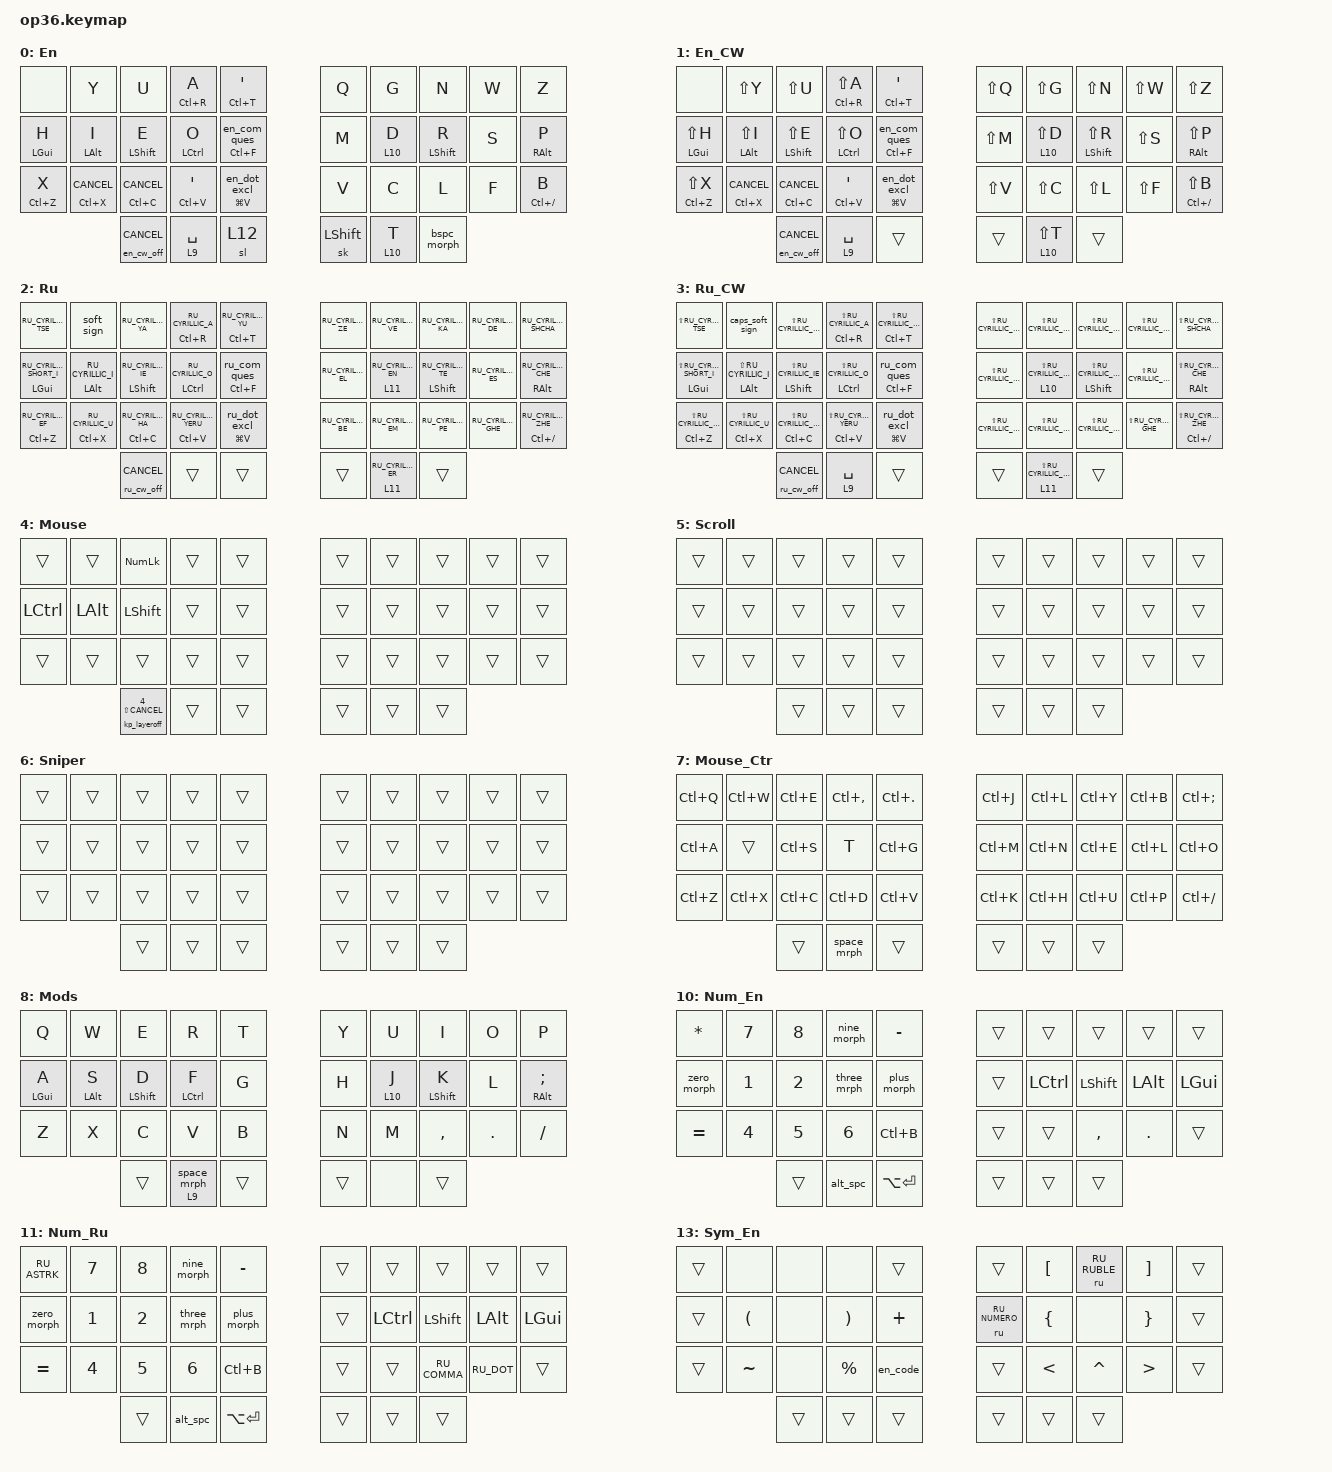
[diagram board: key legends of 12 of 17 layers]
#include "keys_ru.h"
#include <dt-bindings/zmk/behaviors.h>
#include <behaviors.dtsi>
#include <dt-bindings/zmk/bt.h>
#include <dt-bindings/zmk/keys.h>
#include <dt-bindings/zmk/outputs.h>
#include <dt-bindings/zmk/pointing.h>

&mt {
    flavor = "tap-preferred";
    tapping-term-ms = <200>;
    bindings = <&kp>, <&kp>;
};

&lt {
    flavor = "balanced";
    bindings = <&mo>, <&long_kp>;
};

&sl { release-after-ms = <5000>; };

&sk {
    release-after-ms = <5000>;
    quick-release;
};

&key_repeat { usage-pages = <HID_USAGE_KEY HID_USAGE_CONSUMER>; };

/ {
    combos {
        compatible = "zmk,combos";

        combo_ctrl_ent {
            bindings = <&kp LC(ENTER)>;
            key-positions = <1 3>;
            require-prior-idle-ms = <30>;
        };

        combo_enter {
            bindings = <&kp ENTER>;
            key-positions = <2 1>;
            require-prior-idle-ms = <30>;
            timeout-ms = <30>;
        };

        combo_tab {
            bindings = <&kp TAB>;
            key-positions = <11 12>;
            require-prior-idle-ms = <50>;
            timeout-ms = <30>;
        };

        combo_esc {
            bindings = <&kp ESC>;
            key-positions = <21 22>;
            require-prior-idle-ms = <30>;
            timeout-ms = <30>;
        };

        combo_ru {
            bindings = <&layer_ru>;
            key-positions = <23 22>;
            timeout-ms = <30>;
            require-prior-idle-ms = <(-1)>;
        };

        combo_en {
            bindings = <&layer_en>;
            key-positions = <26 27>;
            timeout-ms = <30>;
            require-prior-idle-ms = <(-1)>;
        };

        combo_osl_sym_en {
            bindings = <&sl 13>;
            key-positions = <16 17>;
            require-prior-idle-ms = <50>;
            layers = <0 1 13>;
        };

        combo_lessgreater_en {
            bindings = <&less_greater_en>;
            require-prior-idle-ms = <30>;
            key-positions = <26 28>;
            layers = <0 1 13>;
        };

        combo_osl_sym_ru {
            bindings = <&sl 14>;
            key-positions = <16 17>;
            require-prior-idle-ms = <50>;
            layers = <2 3 14>;
        };

        combo_lessgreater_ru {
            bindings = <&less_greater_ru>;
            key-positions = <26 28>;
            require-prior-idle-ms = <30>;
            layers = <2 3>;
        };

        combo_braces_en {
            bindings = <&braces_en>;
            key-positions = <16 18>;
            require-prior-idle-ms = <50>;
            layers = <0 1 13>;
        };

        combo_singlequote_ru {
            bindings = <&en SINGLE_QUOTE>;
            timeout-ms = <30>;
            key-positions = <6 5>;
            layers = <2 3 14 11>;
        };

        combo_slash_ru {
            bindings = <&kp RU_SLASH>;
            timeout-ms = <30>;
            key-positions = <27 28>;
            layers = <2 3 14 11>;
        };

        combo_singequote_en {
            bindings = <&kp SINGLE_QUOTE>;
            timeout-ms = <30>;
            key-positions = <6 5>;
            layers = <0 1 10 13>;
        };

        combo_slash_en {
            bindings = <&kp SLASH>;
            timeout-ms = <30>;
            key-positions = <27 28>;
            layers = <0 1 10 13>;
        };

        combo_capsword_en {
            bindings = <&to 1>;
            key-positions = <11 10>;
            layers = <0 1>;
        };

        combo_osl_fn {
            bindings = <&sl 15>;
            key-positions = <21 23>;
        };

        combo_osl_os {
            bindings = <&sl 16>;
            key-positions = <20 21>;
        };

        combo_capsword_ru {
            bindings = <&to 3>;
            key-positions = <11 10>;
            layers = <2 3>;
        };

        combo_yo_ru {
            bindings = <&kp RU_CYRILLIC_IO>;
            key-positions = <21 22 23>;
            layers = <2>;
        };

        combo_yo_cw_ru {
            bindings = <&kp LS(RU_CYRILLIC_IO)>;
            key-positions = <21 22 23>;
            layers = <3>;
        };

        combo_yo_en {
            bindings = <&ru RU_CYRILLIC_IO>;
            key-positions = <21 22 23>;
            layers = <0>;
        };

        parentheses {
            bindings = <&parentheses>;
            key-positions = <11 13>;
            timeout-ms = <30>;
            require-prior-idle-ms = <50>;
        };

        combo_braces_ru {
            bindings = <&braces_ru>;
            key-positions = <16 18>;
            timeout-ms = <25>;
            layers = <2 3 14>;
            require-prior-idle-ms = <50>;
        };

        combo_brackets_en {
            bindings = <&brackets_en>;
            key-positions = <6 8>;
            layers = <0 1 13>;
            timeout-ms = <30>;
            require-prior-idle-ms = <30>;
        };

        combo_brackets_ru {
            bindings = <&brackets_ru>;
            key-positions = <6 8>;
            layers = <2 3 14>;
            timeout-ms = <30>;
        };

        combo_minus {
            bindings = <&kp MINUS>;
            key-positions = <2 3>;
            require-prior-idle-ms = <30>;
            timeout-ms = <30>;
        };

        combo_grave_ru {
            bindings = <&en GRAVE>;
            key-positions = <16 15>;
            layers = <2 3 14>;
        };

        combo_grave_en {
            bindings = <&kp GRAVE>;
            key-positions = <16 15>;
            layers = <0 1 13>;
        };

        combo_under {
            bindings = <&kp UNDER>;
            key-positions = <3 4>;
            require-prior-idle-ms = <30>;
            timeout-ms = <30>;
        };

        combo_ru_at {
            bindings = <&en AT>;
            key-positions = <11 12 13>;
            layers = <2 3 14>;
        };

        combo_en_at {
            bindings = <&kp AT>;
            key-positions = <11 12 13>;
            layers = <0 1 13>;
        };

        combo_quotes_en {
            bindings = <&td_quotes_en>;
            key-positions = <6 7>;
            layers = <0 1 10 13>;
        };

        combo_quotes_ru {
            bindings = <&td_quotes_ru>;
            key-positions = <6 7>;
            layers = <2 3 14 11>;
        };

        combo_en_amp {
            bindings = <&kp AMPS>;
            key-positions = <7 8>;
            layers = <0 1 10 13>;
        };

        combo_en_semi {
            bindings = <&kp SEMI>;
            key-positions = <13 14>;
            layers = <0 1 10 13>;
        };

        combo_ru_semi {
            bindings = <&kp RU_SEMI>;
            key-positions = <13 14>;
            layers = <2 3 11 14>;
        };

        combo_amp_ru {
            bindings = <&en AMPS>;
            key-positions = <7 8>;
            layers = <2 3 11 14>;
        };

        combo_en_colon {
            bindings = <&kp COLON>;
            key-positions = <23 24>;
            layers = <0 1 10 13>;
        };

        combo_ru_colon {
            bindings = <&kp RU_COLON>;
            key-positions = <23 24>;
            layers = <2 3 10 13>;
        };

        combo_backslash_ru {
            bindings = <&kp RU_BACKSLASH>;
            key-positions = <28 29>;
            layers = <2 3 11 14>;
        };

        combo_backslash_en {
            bindings = <&kp BACKSLASH>;
            key-positions = <28 29>;
            layers = <0 1 10 13>;
        };

        combo_arrow_ru {
            bindings = <&arrow_ru>;
            key-positions = <26 27 28>;
            layers = <2 3 11 14>;
        };

        combo_arrow_en {
            bindings = <&arrow_en>;
            key-positions = <26 27 28>;
            layers = <0 1 10 13>;
        };

        combo_pipe_ru {
            bindings = <&en PIPE>;
            key-positions = <7 8 6>;
            layers = <2 3 11 14>;
        };

        combo_pipe_en {
            bindings = <&kp PIPE>;
            key-positions = <6 7 8>;
            layers = <0 1 10 13>;
        };

        combo_dollar_ru {
            bindings = <&en DOLLAR>;
            key-positions = <16 17 18>;
            layers = <2 3 11 14>;
        };

        combo_dollar_en {
            bindings = <&kp DOLLAR>;
            key-positions = <16 17 18>;
            layers = <0 1 10 13>;
        };

        combo_hash_ru {
            bindings = <&en HASH>;
            key-positions = <25 26>;
            layers = <2 3 11 14>;
        };

        combo_hash_en {
            bindings = <&kp HASH>;
            key-positions = <25 26>;
            layers = <0 1 10 13>;
        };

        combo_asterisk {
            bindings = <&kp RU_ASTERISK>;
            key-positions = <1 2 3>;
        };

        cmb_j {
            bindings = <&kp J>;
            key-positions = <0 1>;
            layers = <0 10 13>;
        };

        cmb_j_cw {
            bindings = <&kp LS(J)>;
            key-positions = <0 1>;
            layers = <1>;
        };

        cmb_k {
            bindings = <&kp K>;
            key-positions = <18 19>;
            layers = <0>;
        };

        combo_k_cw {
            bindings = <&kp LS(K)>;
            key-positions = <18 19>;
            layers = <1>;
        };

        cmb_e {
            bindings = <&kp RU_CYRILLIC_E>;
            key-positions = <0 1>;
            layers = <2>;
        };

        cmb_e_cw {
            bindings = <&kp LS(RU_CYRILLIC_E)>;
            key-positions = <0 1>;
            layers = <3>;
        };

        combo_she {
            bindings = <&kp RU_CYRILLIC_SHA>;
            key-positions = <18 19>;
            layers = <2>;
        };

        cmb_she_cw {
            bindings = <&kp LS(RU_CYRILLIC_SHA)>;
            key-positions = <18 19>;
            layers = <3>;
        };
    };

    macros {
        layer_ru: lg_ru {
            compatible = "zmk,behavior-macro";
            #binding-cells = <0>;
            bindings = <&to 2 &kp LS(LC(N8))>;
            label = "LG_RU";
            tap-ms = <40>;
            wait-ms = <0>;
        };

        layer_en: lg_en {
            compatible = "zmk,behavior-macro";
            #binding-cells = <0>;
            bindings = <&to 0 &kp LS(LC(N9))>;
            label = "LG_EN";
            tap-ms = <40>;
            wait-ms = <0>;
        };

        to_ru: to_ru {
            compatible = "zmk,behavior-macro";
            #binding-cells = <0>;
            bindings = <&kp LC(LS(N8))>;
            label = "TO_RU";
            tap-ms = <40>;
            wait-ms = <0>;
        };

        to_en: to_en {
            compatible = "zmk,behavior-macro";
            #binding-cells = <0>;
            bindings = <&kp LC(LS(N9))>;
            label = "TO_EN";
            wait-ms = <0>;
            tap-ms = <40>;
        };

        en: en {
            compatible = "zmk,behavior-macro-one-param";
            #binding-cells = <1>;
            bindings = <&kp LC(LS(N9)) &macro_param_1to1 &kp MACRO_PLACEHOLDER &kp LC(LS(N8))>;
            label = "EN";
            wait-ms = <10>;
            tap-ms = <40>;
        };

        ru: ru {
            compatible = "zmk,behavior-macro-one-param";
            #binding-cells = <1>;
            bindings = <&kp LC(LS(N8)) &macro_param_1to1 &kp MACRO_PLACEHOLDER &kp LS(LC(N9))>;
            label = "RU";
            tap-ms = <40>;
        };

        alt_tab: alt_tab {
            compatible = "zmk,behavior-macro";
            #binding-cells = <0>;
            bindings =
                <&macro_wait_time 30>,
                <&macro_press>,
                <&kp LEFT_ALT>,
                <&macro_tap>,
                <&kp TAB>,
                <&macro_release>,
                <&kp LEFT_ALT>;

            label = "ALT_TAB";
            tap-ms = <30>;
        };

        select_row: select_row {
            compatible = "zmk,behavior-macro";
            #binding-cells = <0>;
            bindings = <&kp END &kp LS(HOME)>;
            label = "SELECT_ROW";
            wait-ms = <0>;
        };

        en_code: en_code_block {
            compatible = "zmk,behavior-macro";
            #binding-cells = <0>;
            bindings = <&kp GRAVE &kp GRAVE &kp GRAVE &kp RETURN &kp RET &kp GRAVE &kp GRAVE &kp GRAVE &kp UP_ARROW>;
            label = "EN_CODE_BLOCK";
            tap-ms = <50>;
        };

        ru_code: ru_code {
            compatible = "zmk,behavior-macro";
            #binding-cells = <0>;
            bindings = <&kp LS(LC(N9)) &kp GRAVE &kp GRAVE &kp GRAVE &kp RETURN &kp RET &kp GRAVE &kp GRAVE &kp GRAVE &kp UP_ARROW &kp LC(LS(N8))>;
            label = "RU_CODE";
            tap-ms = <50>;
            wait-ms = <10>;
        };

        ru_cw_off: ru_cw_off {
            compatible = "zmk,behavior-macro-one-param";
            #binding-cells = <1>;
            bindings = <&macro_param_1to1 &kp MACRO_PLACEHOLDER &to 2>;
            label = "RU_CW_OFF";
            wait-ms = <0>;
        };

        en_cw_off: en_cw_off {
            compatible = "zmk,behavior-macro-one-param";
            #binding-cells = <1>;
            bindings = <&macro_param_1to1 &kp MACRO_PLACEHOLDER &to 0>;
            label = "EN_CW_OFF";
            wait-ms = <0>;
        };

        zeros_macro: zeros_macro {
            compatible = "zmk,behavior-macro";
            #binding-cells = <0>;
            bindings = <&kp N0 &kp N0 &kp N0 &kp N0 &kp N0 &kp N0>;
            label = "ZEROS_MACRO";
        };

        osm_ctrl_shift: osm_ctrl_shift {
            compatible = "zmk,behavior-macro";
            #binding-cells = <0>;
            bindings = <&sk LS(LCTRL) &sl 8>;
            label = "OSM_CTRL_SHIFT";
            wait-ms = <0>;
            tap-ms = <0>;
        };

        ml: ml {
            compatible = "zmk,behavior-macro-one-param";
            #binding-cells = <1>;
            bindings =
                <&macro_param_1to1 &key_on MACRO_PLACEHOLDER &layer_on 8>,
                <&macro_pause_for_release>,
                <&macro_param_1to1 &key_off MACRO_PLACEHOLDER &layer_off 8>;

            label = "Mod Layer";
            wait-ms = <0>;
            tap-ms = <0>;
        };

        quotes_ru: dbl_quote {
            compatible = "zmk,behavior-macro";
            #binding-cells = <0>;
            bindings = <&kp LS(NUMBER_2) &kp LS(NUMBER_2) &kp LEFT_ARROW>;
            label = "DBL_QUOTE";
            wait-ms = <0>;
        };

        quotes_en: quotes_en {
            compatible = "zmk,behavior-macro";
            #binding-cells = <0>;
            bindings = <&kp DOUBLE_QUOTES &kp DOUBLE_QUOTES &kp LEFT_ARROW>;
            label = "QUOTES_EN";
            wait-ms = <0>;
        };

        braces_en: braces_en {
            compatible = "zmk,behavior-macro";
            #binding-cells = <0>;
            bindings = <&kp LEFT_BRACE &kp RIGHT_BRACE &kp LEFT>;
            label = "BRACES_EN";
            wait-ms = <0>;
        };

        braces_ru: braces_ru {
            compatible = "zmk,behavior-macro";
            #binding-cells = <0>;
            bindings = <&to_en &braces_en &to_ru>;
            label = "BRACES_RU";
            wait-ms = <0>;
        };

        brackets_en: brackets_en {
            compatible = "zmk,behavior-macro";
            #binding-cells = <0>;
            bindings = <&kp LEFT_BRACKET &kp RIGHT_BRACKET &kp LEFT_ARROW>;
            label = "BRACKETS_EN";
            wait-ms = <0>;
        };

        brackets_ru: brackets_ru {
            compatible = "zmk,behavior-macro";
            #binding-cells = <0>;
            bindings = <&to_en &brackets_en &to_ru>;
            label = "BRACKETS_RU";
            wait-ms = <0>;
        };

        parentheses: parentheses {
            compatible = "zmk,behavior-macro";
            #binding-cells = <0>;
            bindings = <&kp LEFT_PARENTHESIS &kp RIGHT_PARENTHESIS &kp LEFT_ARROW>;
            label = "PARENTHESES";
            wait-ms = <0>;
        };

        less_greater_en: less_greater_en {
            compatible = "zmk,behavior-macro";
            #binding-cells = <0>;
            bindings = <&kp LESS_THAN &kp GREATER_THAN &kp LEFT>;
            label = "LESS_GREATER_EN";
            wait-ms = <0>;
        };

        less_greater_ru: less_greater_ru {
            compatible = "zmk,behavior-macro";
            #binding-cells = <0>;
            bindings = <&kp LS(LC(N9)) &less_greater_en &kp LS(LC(N8))>;
            label = "LESS_GREATER_RU";
        };

        osm_ctrl: osm_ctrl {
            compatible = "zmk,behavior-macro";
            #binding-cells = <0>;
            bindings = <&sk LCTRL &sl 8>;
            label = "OSM_CTRL";
            wait-ms = <0>;
            tap-ms = <0>;
        };

        sync_lg: sync_lg {
            compatible = "zmk,behavior-macro";
            #binding-cells = <0>;
            bindings = <&tog 2>;
            label = "SYNC_LG";
        };

        alt_spc: alt_spc {
            compatible = "zmk,behavior-macro";
            #binding-cells = <0>;
            bindings = <&kp LA(SPACE) &layer_off 4>;
            label = "ALT_SPC";
            wait-ms = <0>;
            tap-ms = <0>;
        };

        kp_layeroff: cancel_msoff {
            compatible = "zmk,behavior-macro-two-param";
            #binding-cells = <2>;
            bindings = <&macro_param_1to1 &layer_off MACRO_PLACEHOLDER &macro_param_2to1 &kp MACRO_PLACEHOLDER>;
            label = "CANCEL_MSOFF";
        };

        dkp: dkp {
            compatible = "zmk,behavior-macro-two-param";
            #binding-cells = <2>;
            bindings =
                <&macro_press>,
                <&macro_param_1to1 &kp MACRO_PLACEHOLDER &macro_param_2to1 &kp MACRO_PLACEHOLDER>,
                <&macro_pause_for_release>,
                <&macro_release>,
                <&macro_param_1to1 &kp MACRO_PLACEHOLDER &macro_param_2to1 &kp MACRO_PLACEHOLDER>;

            label = "DKP";
            wait-ms = <0>;
            tap-ms = <0>;
        };

        osm_shift: osm_shift {
            compatible = "zmk,behavior-macro";
            #binding-cells = <0>;
            bindings = <&sk LEFT_SHIFT &sl 8>;
            label = "OSM_SHIFT";
            wait-ms = <0>;
            tap-ms = <0>;
        };

        dbl_tap: dbl_tap {
            compatible = "zmk,behavior-macro-one-param";
            #binding-cells = <1>;
            bindings = <&macro_param_1to1 &kp MACRO_PLACEHOLDER &macro_param_1to1 &kp MACRO_PLACEHOLDER>;
            label = "DBL_TAP";
            tap-ms = <50>;
            wait-ms = <20>;
        };

        select_word: select_word {
            compatible = "zmk,behavior-macro";
            #binding-cells = <0>;
            bindings = <&kp LC(LEFT) &kp LC(LS(RIGHT))>;
            label = "SELECT_WORD";
        };

        kp_: kp_ {
            compatible = "zmk,behavior-macro-one-param";
            #binding-cells = <1>;
            bindings =
                <&macro_press>,
                <&macro_param_1to1 &kp MACRO_PLACEHOLDER>,
                <&macro_pause_for_release>,
                <&macro_release>,
                <&macro_param_1to1 &kp MACRO_PLACEHOLDER>;

            label = "KP_";
        };

        multi_kp: multi_kp {
            compatible = "zmk,behavior-macro-one-param";
            #binding-cells = <1>;
            bindings = <&macro_param_1to1 &kp MACRO_PLACEHOLDER &macro_param_1to1 &kp MACRO_PLACEHOLDER>;
            label = "MULTI_KP";
            tap-ms = <200>;
        };

        dbl_grave_ru: dbl_grave_ru {
            compatible = "zmk,behavior-macro";
            #binding-cells = <0>;
            bindings = <&kp LS(LC(N9)) &kp GRAVE &kp GRAVE &kp LEFT_ARROW &kp LS(LC(N8))>;
            label = "DBL_GRAVE_RU";
            wait-ms = <0>;
        };

        dbl_grave_en: dbl_grave_en {
            compatible = "zmk,behavior-macro";
            #binding-cells = <0>;
            bindings = <&kp GRAVE &kp GRAVE &kp LEFT_ARROW>;
            label = "DBL_GRAVE_EN";
            wait-ms = <0>;
        };

        triple_press: triple_press {
            compatible = "zmk,behavior-macro-one-param";
            #binding-cells = <1>;
            bindings = <&macro_param_1to1 &kp MACRO_PLACEHOLDER &macro_param_1to1 &kp MACRO_PLACEHOLDER &macro_param_1to1 &kp MACRO_PLACEHOLDER>;
            label = "TRIPLE_PRESS";
        };

        triple_press_en: triple_press_en {
            compatible = "zmk,behavior-macro-one-param";
            #binding-cells = <1>;
            bindings = <&kp N9 &macro_param_1to1 &kp MACRO_PLACEHOLDER &macro_param_1to1 &kp MACRO_PLACEHOLDER &macro_param_1to1 &kp MACRO_PLACEHOLDER &kp LS(LC(N8))>;
            label = "TRIPLE_PRESS_EN";
        };

        testops: testops {
            compatible = "zmk,behavior-macro";
            #binding-cells = <0>;
            bindings = <&kp LS(LC(LG(F7))) &kp LS(LC(LG(F8)))>;
            label = "TESTOPS";
            wait-ms = <500>;
            tap-ms = <150>;
        };

        long_kp: long_kp {
            compatible = "zmk,behavior-macro-one-param";
            #binding-cells = <1>;
            bindings =
                <&macro_press>,
                <&macro_param_1to1 &kp MACRO_PLACEHOLDER>,
                <&macro_pause_for_release>,
                <&macro_release>,
                <&macro_param_1to1 &kp MACRO_PLACEHOLDER>;

            label = "LONG_KP";
            wait-ms = <50>;
        };

        bt_set: bt_set {
            compatible = "zmk,behavior-macro-one-param";
            #binding-cells = <1>;
            bindings = <&out OUT_BLE &macro_param_1to2 &bt BT_SEL MACRO_PLACEHOLDER>;
            label = "BT_SET";
        };

        arrow_en: arrow_en {
            compatible = "zmk,behavior-macro";
            #binding-cells = <0>;
            bindings = <&kp MINUS &kp GREATER_THAN>;
            label = "ARROW_EN";
        };

        arrow_ru: arrow_ru {
            compatible = "zmk,behavior-macro";
            #binding-cells = <0>;
            bindings = <&to_en &arrow_en &to_ru>;
            label = "ARROW_RU";
        };

        bt_set_c: bt_set_c {
            compatible = "zmk,behavior-macro-one-param";
            #binding-cells = <1>;
            bindings = <&macro_param_1to1 &bt_set MACRO_PLACEHOLDER &layer_off 16>;
            label = "BT_SET_C";
        };
    };

    behaviors {
        layer_off: layer_off {
            compatible = "zmk,behavior-toggle-layer";
            label = "LAYER_OFF";
            #binding-cells = <1>;
            toggle-mode = "off";
        };

        hrm: hrm {
            compatible = "zmk,behavior-hold-tap";
            label = "Home Row Mod";
            bindings = <&kp>, <&kp>;

            #binding-cells = <2>;
            tapping-term-ms = <200>;
            flavor = "balanced";
        };

        hrm_slow: hrm_slow {
            compatible = "zmk,behavior-hold-tap";
            label = "HRM for slow fingers";
            bindings = <&kp>, <&kp>;

            #binding-cells = <2>;
            flavor = "tap-preferred";
            tapping-term-ms = <200>;
        };

        ru_lt_cw_off: ru_lt_cw_off {
            compatible = "zmk,behavior-hold-tap";
            label = "RU_LT_CW_OFF";
            bindings = <&mo>, <&ru_cw_off>;

            #binding-cells = <2>;
            tapping-term-ms = <180>;
            flavor = "balanced";
        };

        en_lt_cw_off: en_lt_cw_off {
            compatible = "zmk,behavior-hold-tap";
            label = "EN_LT_CW_OFF";
            bindings = <&mo>, <&en_cw_off>;

            #binding-cells = <2>;
            tapping-term-ms = <180>;
            flavor = "balanced";
        };

        hrl: hrl {
            compatible = "zmk,behavior-hold-tap";
            label = "Home Row Layer";
            bindings = <&mo>, <&kp>;

            #binding-cells = <2>;
            tapping-term-ms = <200>;
            flavor = "balanced";
        };

        bspc_morph: bspc_morph {
            compatible = "zmk,behavior-mod-morph";
            label = "BSPC_MORPH";
            bindings = <&kp BACKSPACE>, <&kp DELETE>;

            #binding-cells = <0>;
            mods = <(MOD_LALT)>;
        };

        key_on: key_on {
            compatible = "zmk,behavior-key-toggle";
            label = "KEY_ON";
            #binding-cells = <1>;
        };

        key_off: key_off {
            compatible = "zmk,behavior-key-toggle";
            label = "KEY_OFF";
            #binding-cells = <1>;
            toggle-mode = "off";
        };

        hrml: hrml {
            compatible = "zmk,behavior-hold-tap";
            label = "Home Row Mod Layer";
            bindings = <&ml>, <&kp>;

            #binding-cells = <2>;
            tapping-term-ms = <200>;
            flavor = "balanced";
            hold-trigger-key-positions = <1 2 3 5 6 7 8 9 10 12 13 14 15 16 17 18 19 20 21 22 23 25 26 27 28 29 30 31 32 33 34 42 43 39>;
        };

        layer_on: layer_on {
            compatible = "zmk,behavior-toggle-layer";
            label = "LAYER_ON";
            #binding-cells = <1>;
            toggle-mode = "on";
        };

        hrml_slow: hrml_slow {
            compatible = "zmk,behavior-hold-tap";
            label = "HRML for slow fingers";
            bindings = <&ml>, <&kp>;

            #binding-cells = <2>;
            tapping-term-ms = <200>;
            flavor = "tap-preferred";
        };

        soft_sign: soft_sign {
            compatible = "zmk,behavior-mod-morph";
            label = "SOFT_SIGN";
            bindings = <&kp RU_CYRILLIC_SOFT_SIGN>, <&kp RU_CYRILLIC_HARD_SIGN>;

            #binding-cells = <0>;
            mods = <(MOD_LSFT)>;
        };

        en_dot_excl: en_dot_excl {
            compatible = "zmk,behavior-mod-morph";
            label = "EN_DOT_EXCL";
            bindings = <&en_cw_off DOT>, <&en_cw_off EXCL>;

            #binding-cells = <0>;
            mods = <(MOD_LSFT)>;
        };

        en_com_ques: en_com_ques {
            compatible = "zmk,behavior-mod-morph";
            label = "EN_COM_QUES";
            bindings = <&en_cw_off COMMA>, <&en_cw_off QUESTION>;

            #binding-cells = <0>;
            mods = <(MOD_LSFT)>;
        };

        ru_dot_excl: ru_dot_excl {
            compatible = "zmk,behavior-mod-morph";
            label = "RU_DOT_EXCL";
            bindings = <&ru_cw_off RU_DOT>, <&ru_cw_off EXCL>;

            #binding-cells = <0>;
            mods = <(MOD_LSFT)>;
        };

        ru_com_ques: ru_com_ques {
            compatible = "zmk,behavior-mod-morph";
            label = "RU_COM_QUES";
            bindings = <&ru_cw_off RU_COMMA>, <&ru_cw_off RU_QUESTION>;

            #binding-cells = <0>;
            mods = <(MOD_LSFT)>;
        };

        mkp_hold: mkp_hold {
            compatible = "zmk,behavior-hold-tap";
            label = "MKP_HOLD";
            bindings = <&kp>, <&mkp>;

            #binding-cells = <2>;
            tapping-term-ms = <203>;
            flavor = "tap-preferred";
        };

        ru_dot_mt: ru_dot_mt {
            compatible = "zmk,behavior-hold-tap";
            label = "RU_DOT_MT";
            bindings = <&kp>, <&ru_dot_excl>;

            #binding-cells = <2>;
            tapping-term-ms = <200>;
            flavor = "tap-preferred";
        };

        ru_com_mt: ru_com_mt {
            compatible = "zmk,behavior-hold-tap";
            label = "RU_COM_MT";
            bindings = <&kp>, <&ru_com_ques>;

            #binding-cells = <2>;
            tapping-term-ms = <200>;
            flavor = "tap-preferred";
        };

        en_com_mt: en_com_mt {
            compatible = "zmk,behavior-hold-tap";
            label = "EN_COM_MT";
            bindings = <&kp>, <&en_com_ques>;

            #binding-cells = <2>;
            tapping-term-ms = <200>;
            flavor = "balanced";
        };

        en_dot_mt: en_dot_mt {
            compatible = "zmk,behavior-hold-tap";
            label = "EN_DOT_MT";
            bindings = <&kp>, <&en_dot_excl>;

            #binding-cells = <2>;
            tapping-term-ms = <200>;
            flavor = "balanced";
        };

        space_mrph: space_mrph {
            compatible = "zmk,behavior-mod-morph";
            label = "SPACE_MRPH";
            bindings = <&kp SPACE>, <&kp TAB>;

            #binding-cells = <0>;
            mods = <(MOD_LSFT|MOD_RSFT|MOD_LCTL|MOD_RCTL)>;
            keep-mods = <(MOD_LSFT|MOD_RSFT|MOD_LCTL|MOD_RCTL)>;
        };

        nine_morph: nine_morph {
            compatible = "zmk,behavior-mod-morph";
            label = "NINE_MORPH";
            bindings = <&kp N9>, <&kp LS(LC(R))>;

            #binding-cells = <0>;
            mods = <(MOD_LSFT)>;
        };

        hrs: hrs {
            compatible = "zmk,behavior-hold-tap";
            label = "HRS";
            bindings = <&kp>, <&kp>;

            #binding-cells = <2>;
            tapping-term-ms = <200>;
            flavor = "balanced";
        };

        ru_grave: ru_grave {
            compatible = "zmk,behavior-tap-dance";
            label = "RU_GRAVE";
            #binding-cells = <0>;
            bindings = <&en GRAVE>, <&dbl_grave_ru>, <&triple_press_en GRAVE>;

            tapping-term-ms = <180>;
        };

        en_grave: en_grave {
            compatible = "zmk,behavior-tap-dance";
            label = "EN_GRAVE";
            #binding-cells = <0>;
            bindings = <&kp GRAVE>, <&dbl_grave_en>, <&triple_press GRAVE>;

            tapping-term-ms = <180>;
        };

        caps_soft_sign: caps_soft_sign {
            compatible = "zmk,behavior-mod-morph";
            label = "CAPS_SOFT_SIGN";
            bindings =
                <&kp LS(RU_CYRILLIC_SOFT_SIGN)>,
                <&kp LS(RU_CYRILLIC_HARD_SIGN)>;

            #binding-cells = <0>;
            mods = <(MOD_LSFT)>;
        };

        three_mrph: three_mrph {
            compatible = "zmk,behavior-mod-morph";
            label = "THREE_MRPH";
            bindings = <&kp NUMBER_3>, <&kp LS(LC(F))>;

            #binding-cells = <0>;
            mods = <(MOD_LSFT)>;
        };

        space_lt: space_lt {
            compatible = "zmk,behavior-hold-tap";
            label = "SPACE_LT";
            bindings = <&mo>, <&space_mrph>;

            #binding-cells = <2>;
            tapping-term-ms = <200>;
            flavor = "balanced";
        };

        mod_dtap: mod_dtap {
            compatible = "zmk,behavior-hold-tap";
            label = "MOD_DTAP";
            bindings = <&kp>, <&kp>;

            #binding-cells = <2>;
            tapping-term-ms = <180>;
            flavor = "hold-preferred";
        };

        zero_morph: zero_morph {
            compatible = "zmk,behavior-mod-morph";
            label = "ZERO_MORPH";
            bindings = <&kp N0>, <&kp LS(LC(A))>;

            #binding-cells = <0>;
            mods = <(MOD_LCTL|MOD_LSFT)>;
        };

        plus_morph: plus_morph {
            compatible = "zmk,behavior-mod-morph";
            label = "PLUS_MORPH";
            bindings = <&kp PLUS>, <&kp LS(LC(G))>;

            #binding-cells = <0>;
            mods = <(MOD_LSFT)>;
        };

        hrs_l: hrs_l {
            compatible = "zmk,behavior-hold-tap";
            label = "HRS_L";
            bindings = <&kp>, <&kp>;

            #binding-cells = <2>;
            tapping-term-ms = <200>;
            flavor = "balanced";
            require-prior-idle-ms = <30>;
        };

        hrs_r: hrs_r {
            compatible = "zmk,behavior-hold-tap";
            label = "HRS_R";
            bindings = <&kp>, <&kp>;

            #binding-cells = <2>;
            tapping-term-ms = <200>;
            flavor = "balanced";
            require-prior-idle-ms = <30>;
        };

        cmd_dtap: cmd_dtap {
            compatible = "zmk,behavior-tap-dance";
            label = "CMD_DTAP";
            #binding-cells = <0>;
            bindings = <&kp LEFT_CONTROL>, <&dbl_tap LEFT_COMMAND>;

            tapping-term-ms = <250>;
        };

        td_quotes_ru: td_quotes_ru {
            compatible = "zmk,behavior-tap-dance";
            label = "TD_QUOTES_RU";
            #binding-cells = <0>;
            bindings = <&kp RU_DOUBLE_QUOTES>, <&quotes_ru>;

            tapping-term-ms = <200>;
        };

        td_quotes_en: td_quotes_en {
            compatible = "zmk,behavior-tap-dance";
            label = "TD_QUOTES_EN";
            #binding-cells = <0>;
            bindings = <&kp DOUBLE_QUOTES>, <&quotes_en>;

            tapping-term-ms = <200>;
        };
    };

    keymap {
        compatible = "zmk,keymap";

        En {
            bindings = <
  &none                  &kp Y                  &kp U                &mt LC(R) A          &mt LC(T) APOS                                &kp Q     &kp G        &kp N                &kp W  &kp Z
  &hrml_slow LEFT_GUI H  &hrml_slow LEFT_ALT I  &hrs_l LEFT_SHIFT E  &hrml LCTRL O        &en_com_mt LC(F) 0                            &kp M     &hrl 10 D    &hrs_r LEFT_SHIFT R  &kp S  &hrml_slow RALT P
  &mt LC(Z) X            &mt LC(X) K_CANCEL     &mt LC(C) K_CANCEL   &mt LC(V) SQT        &en_dot_mt LG(V) 0                            &kp V     &kp C        &kp L                &kp F  &mt LC(SLASH) B
                                                                     &en_cw_off K_CANCEL  &lt 9 SPACE         &sl 12    &sk LEFT_SHIFT  &lt 10 T  &bspc_morph
            >;

            display-name = "En";
        };

        En_CW {
            bindings = <
  &none                      &kp LS(Y)                  &kp LS(U)                &mt LC(R) LS(A)      &mt LC(T) APOS                           &kp LS(Q)     &kp LS(G)      &kp LS(N)                &kp LS(W)  &kp LS(Z)
  &hrml_slow LEFT_GUI LS(H)  &hrml_slow LEFT_ALT LS(I)  &hrs_l LEFT_SHIFT LS(E)  &hrml LCTRL LS(O)    &en_com_mt LC(F) 0                       &kp LS(M)     &hrl 10 LS(D)  &hrs_r LEFT_SHIFT LS(R)  &kp LS(S)  &hrml_slow RALT LS(P)
  &mt LC(Z) LS(X)            &mt LC(X) K_CANCEL         &mt LC(C) K_CANCEL       &mt LC(V) SQT        &en_dot_mt LG(V) 0                       &kp LS(V)     &kp LS(C)      &kp LS(L)                &kp LS(F)  &mt LC(SLASH) LS(B)
                                                                                 &en_cw_off K_CANCEL  &en_lt_cw_off 9 SPACE  &trans    &trans  &lt 10 LS(T)  &trans
            >;

            display-name = "En_CW";
        };

        Ru {
            bindings = <
  &kp RU_CYRILLIC_TSE                      &soft_sign                         &kp RU_CYRILLIC_YA                &mt LC(R) RU_CYRILLIC_A     &mt LC(T) RU_CYRILLIC_YU                    &kp RU_CYRILLIC_ZE     &kp RU_CYRILLIC_VE      &kp RU_CYRILLIC_KA                &kp RU_CYRILLIC_DE   &kp RU_CYRILLIC_SHCHA
  &hrml_slow LEFT_GUI RU_CYRILLIC_SHORT_I  &hrml_slow LEFT_ALT RU_CYRILLIC_I  &hrs_l LEFT_SHIFT RU_CYRILLIC_IE  &hrml LCTRL RU_CYRILLIC_O   &ru_com_mt LC(F) 0                          &kp RU_CYRILLIC_EL     &hrl 11 RU_CYRILLIC_EN  &hrs_r LEFT_SHIFT RU_CYRILLIC_TE  &kp RU_CYRILLIC_ES   &hrml_slow RALT RU_CYRILLIC_CHE
  &mt LC(Z) RU_CYRILLIC_EF                 &mt LC(X) RU_CYRILLIC_U            &mt LC(C) RU_CYRILLIC_HA          &mt LC(V) RU_CYRILLIC_YERU  &ru_dot_mt LG(V) 0                          &kp RU_CYRILLIC_BE     &kp RU_CYRILLIC_EM      &kp RU_CYRILLIC_PE                &kp RU_CYRILLIC_GHE  &mt LC(SLASH) RU_CYRILLIC_ZHE
                                                                                                                &ru_cw_off K_CANCEL         &trans                    &trans    &trans  &lt 11 RU_CYRILLIC_ER  &trans
            >;

            display-name = "Ru";
        };

        Ru_CW {
            bindings = <
  &kp LS(RU_CYRILLIC_TSE)                      &caps_soft_sign                        &kp LS(RU_CYRILLIC_YA)                &mt LC(R) LS(RU_CYRILLIC_A)     &mt LC(T) LS(RU_CYRILLIC_YU)                    &kp LS(RU_CYRILLIC_ZE)     &kp LS(RU_CYRILLIC_VE)      &kp LS(RU_CYRILLIC_KA)                &kp LS(RU_CYRILLIC_DE)   &kp LS(RU_CYRILLIC_SHCHA)
  &hrml_slow LEFT_GUI LS(RU_CYRILLIC_SHORT_I)  &hrml_slow LEFT_ALT LS(RU_CYRILLIC_I)  &hrs_l LEFT_SHIFT LS(RU_CYRILLIC_IE)  &hrml LCTRL LS(RU_CYRILLIC_O)   &ru_com_mt LC(F) 0                              &kp LS(RU_CYRILLIC_EL)     &hrl 10 LS(RU_CYRILLIC_EN)  &hrs_r LEFT_SHIFT LS(RU_CYRILLIC_TE)  &kp LS(RU_CYRILLIC_ES)   &hrml_slow RALT LS(RU_CYRILLIC_CHE)
  &mt LC(Z) LS(RU_CYRILLIC_EF)                 &mt LC(X) LS(RU_CYRILLIC_U)            &mt LC(C) LS(RU_CYRILLIC_HA)          &mt LC(V) LS(RU_CYRILLIC_YERU)  &ru_dot_mt LG(V) 0                              &kp LS(RU_CYRILLIC_BE)     &kp LS(RU_CYRILLIC_EM)      &kp LS(RU_CYRILLIC_PE)                &kp LS(RU_CYRILLIC_GHE)  &mt LC(SLASH) LS(RU_CYRILLIC_ZHE)
                                                                                                                            &ru_cw_off K_CANCEL             &ru_lt_cw_off 9 SPACE         &trans    &trans  &lt 11 LS(RU_CYRILLIC_ER)  &trans
            >;

            display-name = "Ru_CW";
        };

        Mouse {
            bindings = <
  &trans     &trans        &kp KP_NUMLOCK  &trans                       &trans                    &trans  &trans  &trans  &trans  &trans
  &kp LCTRL  &kp LEFT_ALT  &kp LSHFT       &trans                       &trans                    &trans  &trans  &trans  &trans  &trans
  &trans     &trans        &trans          &trans                       &trans                    &trans  &trans  &trans  &trans  &trans
                                           &kp_layeroff 4 LS(K_CANCEL)  &trans  &trans    &trans  &trans  &trans
            >;

            display-name = "Mouse";
        };

        Scroll {
            bindings = <
  &trans  &trans  &trans  &trans  &trans                    &trans  &trans  &trans  &trans  &trans
  &trans  &trans  &trans  &trans  &trans                    &trans  &trans  &trans  &trans  &trans
  &trans  &trans  &trans  &trans  &trans                    &trans  &trans  &trans  &trans  &trans
                          &trans  &trans  &trans    &trans  &trans  &trans
            >;

            display-name = "Scroll";
        };

        Sniper {
            bindings = <
  &trans  &trans  &trans  &trans  &trans                    &trans  &trans  &trans  &trans  &trans
  &trans  &trans  &trans  &trans  &trans                    &trans  &trans  &trans  &trans  &trans
  &trans  &trans  &trans  &trans  &trans                    &trans  &trans  &trans  &trans  &trans
                          &trans  &trans  &trans    &trans  &trans  &trans
            >;

            display-name = "Sniper";
        };

        Mouse_Ctrl {
            bindings = <
  &kp LC(Q)  &kp LC(W)  &kp LC(E)  &kp LC(COMMA)  &kp LC(DOT)                    &kp LC(J)  &kp LC(L)  &kp LC(Y)  &kp LC(B)  &kp LC(SEMI)
  &kp LC(A)  &trans     &kp LC(S)  &kp T          &kp LC(G)                      &kp LC(M)  &kp LC(N)  &kp LC(E)  &kp LC(L)  &kp LC(O)
  &kp LC(Z)  &kp LC(X)  &kp LC(C)  &kp LC(D)      &kp LC(V)                      &kp LC(K)  &kp LC(H)  &kp LC(U)  &kp LC(P)  &kp LC(SLASH)
                                   &trans         &space_mrph  &trans    &trans  &trans     &trans
            >;

            display-name = "Mouse_Ctr";
        };

        Mods {
            bindings = <
  &kp Q             &kp W             &kp E              &kp R         &kp T                            &kp Y  &kp U      &kp I              &kp O    &kp P
  &hrm_slow LGUI A  &hrm_slow LALT S  &hrm LEFT_SHIFT D  &hrm LCTRL F  &kp G                            &kp H  &hrl 10 J  &hrm LEFT_SHIFT K  &kp L    &hrm_slow RALT SEMI
  &kp Z             &kp X             &kp C              &kp V         &kp B                            &kp N  &kp M      &kp COMMA          &kp DOT  &kp SLASH
                                                         &trans        &space_lt 9 0  &trans    &trans  &none  &trans
            >;

            display-name = "Mods";
        };

        Nav {
            bindings = <
  &trans                          &kp LA(LC(GRAVE))                &kp LC(LS(LA(LG(TAB))))  &kp LS(LC(LA(LG(F1))))    &testops                                     &kp PG_UP     &kp HOME      &kp UP    &kp END    &kp DELETE
  &hrm LEFT_GUI LC(LEFT_BRACKET)  &hrm LALT LC(RIGHT_BRACKET)      &kp LSHFT                &mod_dtap LCTRL LEFT_GUI  &zeros_macro                                 &select_word  &kp LEFT      &kp DOWN  &kp RIGHT  &select_row
  &mt LC(Z) LG(LS(LEFT_BRACKET))  &mt LC(X) LG(LS(RIGHT_BRACKET))  &mt LC(C) LS(F6)         &mt LC(V) LS(LC(LA(V)))   &kp LS(LG(LC(F9)))                           &kp PG_DN     &kp CAPSLOCK  &none     &trans     &trans
                                                                                            &trans                    &alt_spc            &kp LA(ENTER)    &trans  &trans        &trans
            >;

            display-name = "Nav";
        };

        Num_En {
            bindings = <
  &kp ASTERISK  &kp NUMBER_7  &kp NUMBER_8  &nine_morph  &kp MINUS                             &trans  &trans     &trans      &trans        &trans
  &zero_morph   &kp N1        &kp N2        &three_mrph  &plus_morph                           &trans  &kp LCTRL  &kp LSHIFT  &kp LEFT_ALT  &kp LEFT_GUI
  &kp EQUAL     &kp N4        &kp N5        &kp N6       &kp LC(B)                             &trans  &trans     &kp COMMA   &kp DOT       &trans
                                            &trans       &alt_spc     &kp LA(ENTER)    &trans  &trans  &trans
            >;

            display-name = "Num_En";
        };

        Num_Ru {
            bindings = <
  &kp RU_ASTRK  &kp NUMBER_7  &kp NUMBER_8  &nine_morph  &kp MINUS                             &trans  &trans     &trans        &trans        &trans
  &zero_morph   &kp N1        &kp N2        &three_mrph  &plus_morph                           &trans  &kp LCTRL  &kp LSHIFT    &kp LEFT_ALT  &kp LEFT_GUI
  &kp EQUAL     &kp N4        &kp N5        &kp N6       &kp LC(B)                             &trans  &trans     &kp RU_COMMA  &kp RU_DOT    &trans
                                            &trans       &alt_spc     &kp LA(ENTER)    &trans  &trans  &trans
            >;

            display-name = "Num_Ru";
        };

        App {
            bindings = <
  &kp LA(LC(LS(P)))  &kp LS(LA(LC(W)))  &kp LS(LA(LC(E)))  &kp LS(LA(LC(R)))  &kp LS(LA(LC(T)))                    &kp LS(LA(LC(Y)))  &kp LS(LA(LC(U)))  &kp LS(LA(LC(I)))      &kp LS(LA(LC(O)))    &kp LS(LA(LC(P)))
  &kp LS(LA(LC(A)))  &kp LS(LA(LC(S)))  &kp LS(LA(LC(D)))  &kp LS(LA(LC(F)))  &kp LS(LA(LC(G)))                    &kp LS(LA(LC(H)))  &kp LS(LA(LC(J)))  &kp LS(LA(LC(K)))      &kp LS(LA(LC(L)))    &kp LS(LA(LC(SEMICOLON)))
  &kp LS(LC(LA(Z)))  &kp LS(LA(LC(X)))  &kp LS(LA(LC(C)))  &kp LS(LC(LG(V)))  &kp LS(LA(LC(B)))                    &kp LS(LA(LC(N)))  &kp LS(LC(LA(M)))  &kp LS(LA(LC(COMMA)))  &kp LS(LA(LC(DOT)))  &kp LS(LC(LA(SLASH)))
                                                           &layer_off 12      &none              &sl 12    &trans  &trans             &trans
            >;

            display-name = "App";
        };

        Sym_En {
            bindings = <
  &trans  &none                 &none  &none                  &trans                      &trans         &kp LEFT_BRACKET  &ru RU_RUBLE  &kp RIGHT_BRACKET  &trans
  &trans  &kp LEFT_PARENTHESIS  &none  &kp RIGHT_PARENTHESIS  &kp PLUS                    &ru RU_NUMERO  &kp LEFT_BRACE    &none         &kp RIGHT_BRACE    &trans
  &trans  &kp TILDE             &none  &kp PERCENT            &en_code                    &trans         &kp LESS_THAN     &kp CARET     &kp GREATER_THAN   &trans
                                       &trans                 &trans    &trans    &trans  &trans         &trans
            >;

            display-name = "Sym_En";
        };

        Sym_Ru {
            bindings = <
  &trans  &none                 &none  &none        &trans                      &trans         &en LEFT_BRACKET  &kp RU_RUBLE  &en RIGHT_BRACKET  &trans
  &trans  &kp LEFT_PARENTHESIS  &none  &kp RPAR     &kp PLUS                    &kp RU_NUMERO  &en LEFT_BRACE    &none         &en RIGHT_BRACE    &trans
  &trans  &en TILDE             &none  &kp PERCENT  &ru_code                    &trans         &en LESS_THAN     &en CARET     &en GREATER_THAN   &trans
                                       &trans       &trans    &trans    &trans  &trans         &trans
            >;

            display-name = "Sym_Ru";
        };

        Fn {
            bindings = <
  &trans   &kp F7  &kp F8  &kp F9  &trans                     &trans  &trans     &trans          &trans    &trans
  &kp F10  &kp F1  &kp F2  &kp F3  &kp F12                    &trans  &kp LCTRL  &kp LEFT_SHIFT  &kp LALT  &kp LEFT_GUI
  &kp F11  &kp F4  &kp F5  &kp F6  &trans                     &trans  &trans     &trans          &trans    &trans
                           &trans  &trans   &trans    &trans  &trans  &trans
            >;

            display-name = "Function";
        };

        OS {
            bindings = <
  &bt_set_c 2  &kp LA(LC(N1))  &kp LA(LC(N2))            &kp LC(LA(NUMBER_3))  &kp LC(LA(NUMBER_4))                    &trans        &studio_unlock  &trans  &trans  &bt BT_CLR
  &bt_set_c 1  &kp LC(RIGHT)   &kp LA(LC(N1))            &kp C_VOLUME_UP       &kp C_BRI_UP                            &out OUT_BLE  &kp F24         &trans  &trans  &soft_off
  &bt_set_c 0  &none           &kp LC(LS(LEFT_BRACKET))  &kp C_VOL_DN          &kp C_BRI_DN                            &out OUT_USB  &kp F23         &trans  &trans  &trans
                                                         &trans                &trans                &trans    &trans  &trans        &trans
            >;

            display-name = "OS";
        };
    };
};
